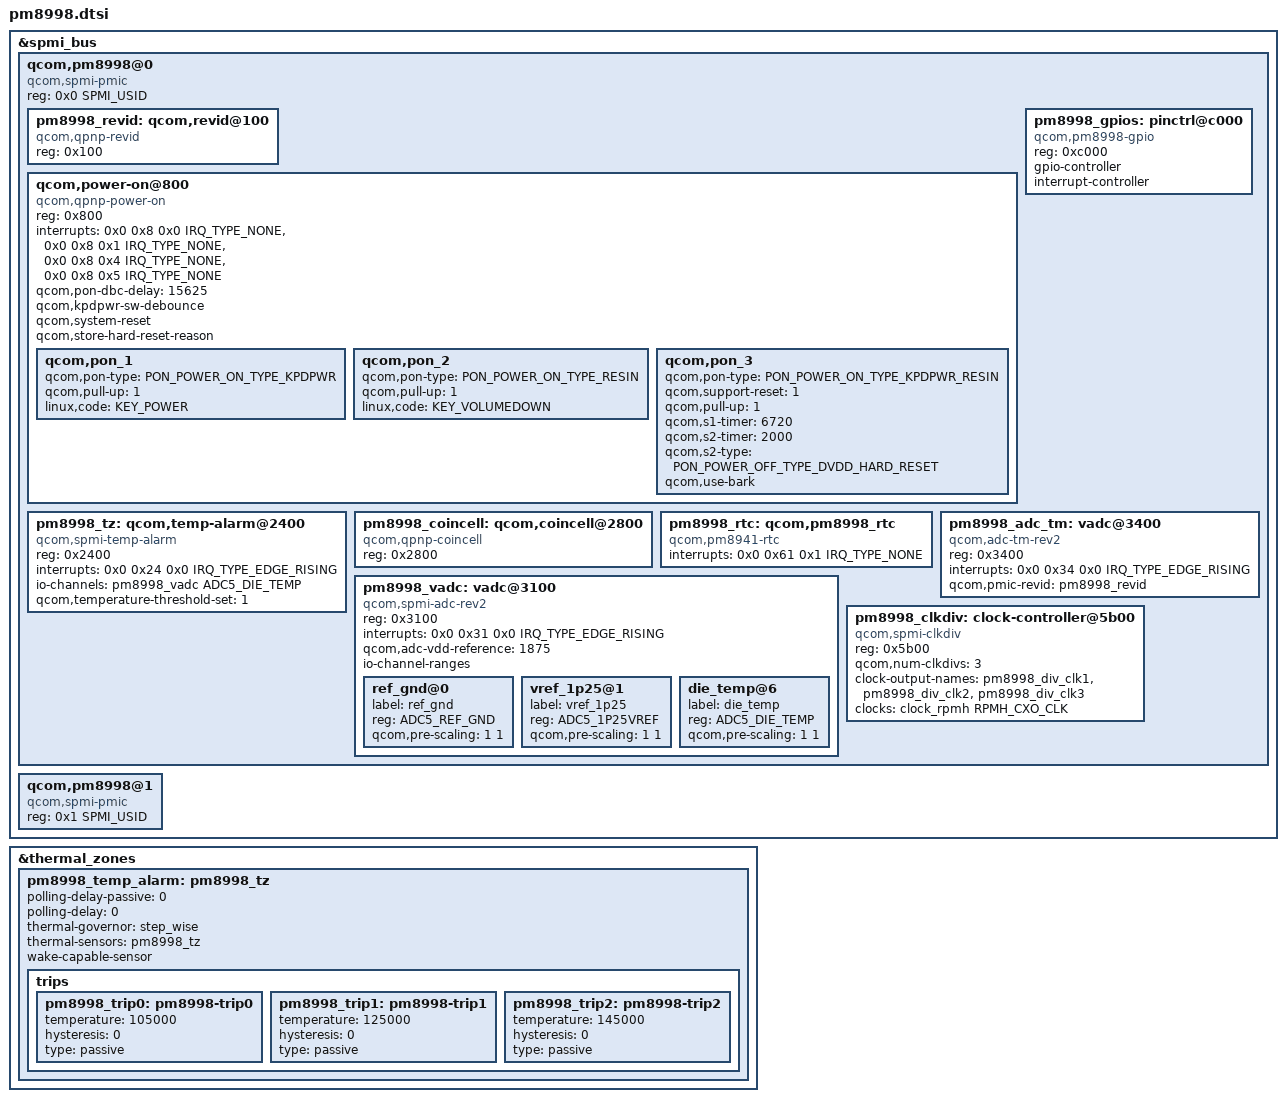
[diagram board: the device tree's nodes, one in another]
// SPDX-License-Identifier: GPL-2.0-only
/*
 * Copyright (c) 2016-2017, 2019, The Linux Foundation. All rights reserved.
 * Copyright (c) 2021, 2025, Pavel Dubrova <pashadubrova@gmail.com>
 */

#include <dt-bindings/input/input.h>
#include <dt-bindings/input/qcom,qpnp-power-on.h>
#include <dt-bindings/interrupt-controller/irq.h>
#include <dt-bindings/spmi/spmi.h>
#include <dt-bindings/iio/qcom,spmi-vadc.h>

&spmi_bus {
	qcom,pm8998@0 {
		compatible = "qcom,spmi-pmic";
		reg = <0x0 SPMI_USID>;
		#address-cells = <1>;
		#size-cells = <0>;

		pm8998_revid: qcom,revid@100 {
			compatible = "qcom,qpnp-revid";
			reg = <0x100>;
		};

		qcom,power-on@800 {
			compatible = "qcom,qpnp-power-on";
			reg = <0x800>;
			interrupts = <0x0 0x8 0x0 IRQ_TYPE_NONE>,
				     <0x0 0x8 0x1 IRQ_TYPE_NONE>,
				     <0x0 0x8 0x4 IRQ_TYPE_NONE>,
				     <0x0 0x8 0x5 IRQ_TYPE_NONE>;
			interrupt-names = "kpdpwr", "resin",
					"resin-bark", "kpdpwr-resin-bark";
			qcom,pon-dbc-delay = <15625>;
			qcom,kpdpwr-sw-debounce;
			qcom,system-reset;
			qcom,store-hard-reset-reason;

			qcom,pon_1 {
				qcom,pon-type = <PON_POWER_ON_TYPE_KPDPWR>;
				qcom,pull-up = <1>;
				linux,code = <KEY_POWER>;
			};

			qcom,pon_2 {
				qcom,pon-type = <PON_POWER_ON_TYPE_RESIN>;
				qcom,pull-up = <1>;
				linux,code = <KEY_VOLUMEDOWN>;
			};

			qcom,pon_3 {
				qcom,pon-type = <PON_POWER_ON_TYPE_KPDPWR_RESIN>;
				qcom,support-reset = <1>;
				qcom,pull-up = <1>;
				qcom,s1-timer = <6720>;
				qcom,s2-timer = <2000>;
				qcom,s2-type = <PON_POWER_OFF_TYPE_DVDD_HARD_RESET>;
				qcom,use-bark;
			};
		};

		pm8998_tz: qcom,temp-alarm@2400 {
			compatible = "qcom,spmi-temp-alarm";
			reg = <0x2400>;
			interrupts = <0x0 0x24 0x0 IRQ_TYPE_EDGE_RISING>;
			io-channels = <&pm8998_vadc ADC5_DIE_TEMP>;
			io-channel-names = "thermal";
			#thermal-sensor-cells = <0>;
			qcom,temperature-threshold-set = <1>;
		};

		pm8998_gpios: pinctrl@c000 {
			compatible = "qcom,pm8998-gpio";
			reg = <0xc000>;
			gpio-controller;
			#gpio-cells = <2>;
			interrupt-controller;
			#interrupt-cells = <2>;
		};

		pm8998_coincell: qcom,coincell@2800 {
			compatible = "qcom,qpnp-coincell";
			reg = <0x2800>;
		};

		pm8998_rtc: qcom,pm8998_rtc {
			compatible = "qcom,pm8941-rtc";
			interrupts = <0x0 0x61 0x1 IRQ_TYPE_NONE>;
		};

		pm8998_vadc: vadc@3100 {
			compatible = "qcom,spmi-adc-rev2";
			reg = <0x3100>;
			#address-cells = <1>;
			#size-cells = <0>;
			interrupts = <0x0 0x31 0x0 IRQ_TYPE_EDGE_RISING>;
			interrupt-names = "eoc-int-en-set";
			qcom,adc-vdd-reference = <1875>;
			#io-channel-cells = <1>;
			io-channel-ranges;

			/* Channel nodes */
			ref_gnd@0 {
				label = "ref_gnd";
				reg = <ADC5_REF_GND>;
				qcom,pre-scaling = <1 1>;
			};

			vref_1p25@1 {
				label = "vref_1p25";
				reg = <ADC5_1P25VREF>;
				qcom,pre-scaling = <1 1>;
			};

			die_temp@6 {
				label = "die_temp";
				reg = <ADC5_DIE_TEMP>;
				qcom,pre-scaling = <1 1>;
			};
		};

		pm8998_adc_tm: vadc@3400 {
			compatible = "qcom,adc-tm-rev2";
			reg = <0x3400>;
			interrupts = <0x0 0x34 0x0 IRQ_TYPE_EDGE_RISING>;
			interrupt-names = "threshold";
			#address-cells = <1>;
			#size-cells = <0>;
			#thermal-sensor-cells = <1>;
			qcom,pmic-revid = <&pm8998_revid>;
		};

		pm8998_clkdiv: clock-controller@5b00 {
			compatible = "qcom,spmi-clkdiv";
			reg = <0x5b00>;
			#clock-cells = <1>;
			qcom,num-clkdivs = <3>;
			clock-output-names = "pm8998_div_clk1",
						"pm8998_div_clk2", "pm8998_div_clk3";
			clocks = <&clock_rpmh RPMH_CXO_CLK>;
			clock-names = "xo";
		};
	};

	qcom,pm8998@1 {
		compatible = "qcom,spmi-pmic";
		reg = <0x1 SPMI_USID>;
		#address-cells = <1>;
		#size-cells = <0>;
	};
};

&thermal_zones {
	pm8998_temp_alarm: pm8998_tz {
		polling-delay-passive = <0>;
		polling-delay = <0>;
		thermal-governor = "step_wise";
		thermal-sensors = <&pm8998_tz>;
		wake-capable-sensor;

		trips {
			pm8998_trip0: pm8998-trip0 {
				temperature = <105000>;
				hysteresis = <0>;
				type = "passive";
			};
			pm8998_trip1: pm8998-trip1 {
				temperature = <125000>;
				hysteresis = <0>;
				type = "passive";
			};
			pm8998_trip2: pm8998-trip2 {
				temperature = <145000>;
				hysteresis = <0>;
				type = "passive";
			};
		};
	};
};
